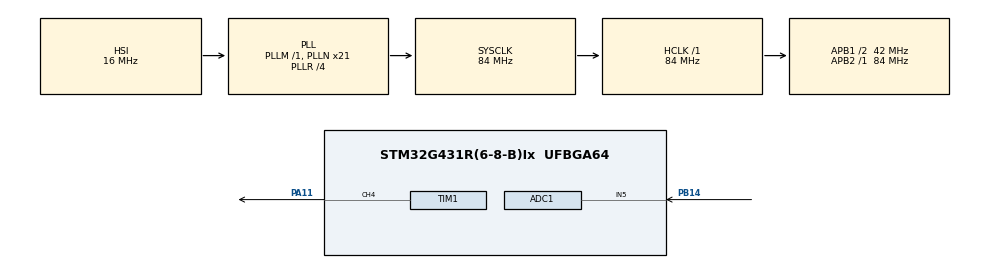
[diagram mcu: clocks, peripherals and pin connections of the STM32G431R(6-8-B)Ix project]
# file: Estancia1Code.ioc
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ADC1.Channel-1\#ChannelRegularConversion=ADC_CHANNEL_5
ADC1.NbrOfConversionFlag=1
ADC1.OffsetNumber-1\#ChannelRegularConversion=ADC_OFFSET_NONE
ADC1.Rank-1\#ChannelRegularConversion=1
ADC1.SamplingTime-1\#ChannelRegularConversion=ADC_SAMPLETIME_2CYCLES_5
ADC1.master=1
Mcu.Family=STM32G4
Mcu.Name=STM32G431R(6-8-B)Ix
Mcu.Package=UFBGA64
NVIC.PriorityGroup=NVIC_PRIORITYGROUP_4
PA11.Signal=S_TIM1_CH4
PA13.GPIO_Label=asd
PA13.Mode=Serial_Wire
PA13.Signal=SYS_JTMS-SWDIO
PA14.GPIO_Label=as
PA14.Mode=Serial_Wire
PA14.Signal=SYS_JTCK-SWCLK
PB14.Mode=IN5-Single-Ended
PB14.Signal=ADC1_IN5
ProjectManager.HeapSize=0x200
ProjectManager.StackSize=0x400
ProjectManager.TargetToolchain=STM32CubeIDE
RCC.ADC12Freq_Value=84000000
RCC.AHBFreq_Value=84000000
RCC.APB1CLKDivider=RCC_HCLK_DIV2
RCC.APB1Freq_Value=42000000
RCC.APB1TimFreq_Value=84000000
RCC.APB2Freq_Value=84000000
RCC.APB2TimFreq_Value=84000000
RCC.CortexFreq_Value=84000000
RCC.EXTERNAL_CLOCK_VALUE=12288000
RCC.HCLKFreq_Value=84000000
RCC.HSE_VALUE=8000000
RCC.HSI48_VALUE=48000000
RCC.HSI_VALUE=16000000
RCC.LSE_VALUE=32768
RCC.PLLN=21
RCC.PLLR=RCC_PLLR_DIV4
RCC.SYSCLKFreq_VALUE=84000000
RCC.SYSCLKSource=RCC_SYSCLKSOURCE_PLLCLK
RCC.USBFreq_Value=168000000
RCC.VCOOutputFreq_Value=336000000
SH.S_TIM1_CH4.0=TIM1_CH4,PWM Generation4 CH4
TIM1.Channel-PWM\ Generation4\ CH4=TIM_CHANNEL_4
VP_SYS_VS_DBSignals.Mode=DisableDeadBatterySignals
VP_TIM1_VS_ClockSourceINT.Mode=Internal
board=custom

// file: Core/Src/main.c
/* USER CODE BEGIN Header */
/**
  ******************************************************************************
  * @file           : main.c
  * @brief          : Main program body
  ******************************************************************************
  * @attention
  *
  * <h2><center>&copy; Copyright (c) 2021 STMicroelectronics.
  * All rights reserved.</center></h2>
  *
  * This software component is licensed by ST under BSD 3-Clause license,
  * the "License"; You may not use this file except in compliance with the
  * License. You may obtain a copy of the License at:
  *                        opensource.org/licenses/BSD-3-Clause
  *
  ******************************************************************************
  */
/* USER CODE END Header */
#include "main.h"

/* USER CODE BEGIN Includes */
#include "leds.h"
#include "motor.h"
#include "pwm.h"
#include "adc.h"
#include "lcd.h"
/* USER CODE END Includes */

ADC_HandleTypeDef hadc1;

TIM_HandleTypeDef htim1;

void SystemClock_Config(void);
static void MX_GPIO_Init(void);
static void MX_ADC1_Init(void);
static void MX_TIM1_Init(void);

int main(void)
{

  /* MCU Configuration--------------------------------------------------------*/

  /* Reset of all peripherals, Initializes the Flash interface and the Systick. */
  HAL_Init();

  /* Configure the system clock */
  SystemClock_Config();

  /* Initialize all configured peripherals */
  MX_GPIO_Init();
  MX_ADC1_Init();
  MX_TIM1_Init();
  /* USER CODE BEGIN 2 */

	vLcd_Init();
	vInit_Leds();
	vMotor_Init();
	vPwm_Init();

  /* USER CODE END 2 */

  /* Infinite loop */
  while (1)
  {

    /* USER CODE BEGIN 3 */
		vLedFunction();
		vDirection();
		vDecreaseAndCreaseVel();
		vConvertIntToASCII();
		HAL_Delay(1);
  }
  /* USER CODE END 3 */
}

void SystemClock_Config(void)
{
  RCC_OscInitTypeDef RCC_OscInitStruct = {0};
  RCC_ClkInitTypeDef RCC_ClkInitStruct = {0};
  RCC_PeriphCLKInitTypeDef PeriphClkInit = {0};

  /** Configure the main internal regulator output voltage
  */
  HAL_PWREx_ControlVoltageScaling(PWR_REGULATOR_VOLTAGE_SCALE1);
  /** Initializes the RCC Oscillators according to the specified parameters
  * in the RCC_OscInitTypeDef structure.
  */
  RCC_OscInitStruct.OscillatorType = RCC_OSCILLATORTYPE_HSI;
  RCC_OscInitStruct.HSIState = RCC_HSI_ON;
  RCC_OscInitStruct.HSICalibrationValue = RCC_HSICALIBRATION_DEFAULT;
  RCC_OscInitStruct.PLL.PLLState = RCC_PLL_ON;
  RCC_OscInitStruct.PLL.PLLSource = RCC_PLLSOURCE_HSI;
  RCC_OscInitStruct.PLL.PLLM = RCC_PLLM_DIV1;
  RCC_OscInitStruct.PLL.PLLN = 21;
  RCC_OscInitStruct.PLL.PLLP = RCC_PLLP_DIV2;
  RCC_OscInitStruct.PLL.PLLQ = RCC_PLLQ_DIV2;
  RCC_OscInitStruct.PLL.PLLR = RCC_PLLR_DIV4;
  if (HAL_RCC_OscConfig(&RCC_OscInitStruct) != HAL_OK)
  {
    Error_Handler();
  }
  /** Initializes the CPU, AHB and APB buses clocks
  */
  RCC_ClkInitStruct.ClockType = RCC_CLOCKTYPE_HCLK|RCC_CLOCKTYPE_SYSCLK
                              |RCC_CLOCKTYPE_PCLK1|RCC_CLOCKTYPE_PCLK2;
  RCC_ClkInitStruct.SYSCLKSource = RCC_SYSCLKSOURCE_PLLCLK;
  RCC_ClkInitStruct.AHBCLKDivider = RCC_SYSCLK_DIV1;
  RCC_ClkInitStruct.APB1CLKDivider = RCC_HCLK_DIV2;
  RCC_ClkInitStruct.APB2CLKDivider = RCC_HCLK_DIV1;

  if (HAL_RCC_ClockConfig(&RCC_ClkInitStruct, FLASH_LATENCY_2) != HAL_OK)
  {
    Error_Handler();
  }
  /** Initializes the peripherals clocks
  */
  PeriphClkInit.PeriphClockSelection = RCC_PERIPHCLK_ADC12;
  PeriphClkInit.Adc12ClockSelection = RCC_ADC12CLKSOURCE_SYSCLK;
  if (HAL_RCCEx_PeriphCLKConfig(&PeriphClkInit) != HAL_OK)
  {
    Error_Handler();
  }
}

static void MX_ADC1_Init(void)
{

  ADC_MultiModeTypeDef multimode = {0};
  ADC_ChannelConfTypeDef sConfig = {0};

  /** Common config
  */
  hadc1.Instance = ADC1;
  hadc1.Init.ClockPrescaler = ADC_CLOCK_SYNC_PCLK_DIV2;
  hadc1.Init.Resolution = ADC_RESOLUTION_12B;
  hadc1.Init.DataAlign = ADC_DATAALIGN_RIGHT;
  hadc1.Init.GainCompensation = 0;
  hadc1.Init.ScanConvMode = ADC_SCAN_DISABLE;
  hadc1.Init.EOCSelection = ADC_EOC_SINGLE_CONV;
  hadc1.Init.LowPowerAutoWait = DISABLE;
  hadc1.Init.ContinuousConvMode = DISABLE;
  hadc1.Init.NbrOfConversion = 1;
  hadc1.Init.DiscontinuousConvMode = DISABLE;
  hadc1.Init.ExternalTrigConv = ADC_SOFTWARE_START;
  hadc1.Init.ExternalTrigConvEdge = ADC_EXTERNALTRIGCONVEDGE_NONE;
  hadc1.Init.DMAContinuousRequests = DISABLE;
  hadc1.Init.Overrun = ADC_OVR_DATA_PRESERVED;
  hadc1.Init.OversamplingMode = DISABLE;
  if (HAL_ADC_Init(&hadc1) != HAL_OK)
  {
    Error_Handler();
  }
  /** Configure the ADC multi-mode
  */
  multimode.Mode = ADC_MODE_INDEPENDENT;
  if (HAL_ADCEx_MultiModeConfigChannel(&hadc1, &multimode) != HAL_OK)
  {
    Error_Handler();
  }
  /** Configure Regular Channel
  */
  sConfig.Channel = ADC_CHANNEL_5;
  sConfig.Rank = ADC_REGULAR_RANK_1;
  sConfig.SamplingTime = ADC_SAMPLETIME_2CYCLES_5;
  sConfig.SingleDiff = ADC_SINGLE_ENDED;
  sConfig.OffsetNumber = ADC_OFFSET_NONE;
  sConfig.Offset = 0;
  if (HAL_ADC_ConfigChannel(&hadc1, &sConfig) != HAL_OK)
  {
    Error_Handler();
  }

}

static void MX_TIM1_Init(void)
{

  TIM_ClockConfigTypeDef sClockSourceConfig = {0};
  TIM_MasterConfigTypeDef sMasterConfig = {0};
  TIM_OC_InitTypeDef sConfigOC = {0};
  TIM_BreakDeadTimeConfigTypeDef sBreakDeadTimeConfig = {0};

  htim1.Instance = TIM1;
  htim1.Init.Prescaler = 0;
  htim1.Init.CounterMode = TIM_COUNTERMODE_UP;
  htim1.Init.Period = 65535;
  htim1.Init.ClockDivision = TIM_CLOCKDIVISION_DIV1;
  htim1.Init.RepetitionCounter = 0;
  htim1.Init.AutoReloadPreload = TIM_AUTORELOAD_PRELOAD_DISABLE;
  if (HAL_TIM_Base_Init(&htim1) != HAL_OK)
  {
    Error_Handler();
  }
  sClockSourceConfig.ClockSource = TIM_CLOCKSOURCE_INTERNAL;
  if (HAL_TIM_ConfigClockSource(&htim1, &sClockSourceConfig) != HAL_OK)
  {
    Error_Handler();
  }
  if (HAL_TIM_PWM_Init(&htim1) != HAL_OK)
  {
    Error_Handler();
  }
  sMasterConfig.MasterOutputTrigger = TIM_TRGO_RESET;
  sMasterConfig.MasterOutputTrigger2 = TIM_TRGO2_RESET;
  sMasterConfig.MasterSlaveMode = TIM_MASTERSLAVEMODE_DISABLE;
  if (HAL_TIMEx_MasterConfigSynchronization(&htim1, &sMasterConfig) != HAL_OK)
  {
    Error_Handler();
  }
  sConfigOC.OCMode = TIM_OCMODE_PWM1;
  sConfigOC.Pulse = 0;
  sConfigOC.OCPolarity = TIM_OCPOLARITY_HIGH;
  sConfigOC.OCNPolarity = TIM_OCNPOLARITY_HIGH;
  sConfigOC.OCFastMode = TIM_OCFAST_DISABLE;
  sConfigOC.OCIdleState = TIM_OCIDLESTATE_RESET;
  sConfigOC.OCNIdleState = TIM_OCNIDLESTATE_RESET;
  if (HAL_TIM_PWM_ConfigChannel(&htim1, &sConfigOC, TIM_CHANNEL_4) != HAL_OK)
  {
    Error_Handler();
  }
  sBreakDeadTimeConfig.OffStateRunMode = TIM_OSSR_DISABLE;
  sBreakDeadTimeConfig.OffStateIDLEMode = TIM_OSSI_DISABLE;
  sBreakDeadTimeConfig.LockLevel = TIM_LOCKLEVEL_OFF;
  sBreakDeadTimeConfig.DeadTime = 0;
  sBreakDeadTimeConfig.BreakState = TIM_BREAK_DISABLE;
  sBreakDeadTimeConfig.BreakPolarity = TIM_BREAKPOLARITY_HIGH;
  sBreakDeadTimeConfig.BreakFilter = 0;
  sBreakDeadTimeConfig.BreakAFMode = TIM_BREAK_AFMODE_INPUT;
  sBreakDeadTimeConfig.Break2State = TIM_BREAK2_DISABLE;
  sBreakDeadTimeConfig.Break2Polarity = TIM_BREAK2POLARITY_HIGH;
  sBreakDeadTimeConfig.Break2Filter = 0;
  sBreakDeadTimeConfig.Break2AFMode = TIM_BREAK_AFMODE_INPUT;
  sBreakDeadTimeConfig.AutomaticOutput = TIM_AUTOMATICOUTPUT_DISABLE;
  if (HAL_TIMEx_ConfigBreakDeadTime(&htim1, &sBreakDeadTimeConfig) != HAL_OK)
  {
    Error_Handler();
  }
  HAL_TIM_MspPostInit(&htim1);

}

static void MX_GPIO_Init(void)
{

  /* GPIO Ports Clock Enable */
  __HAL_RCC_GPIOA_CLK_ENABLE();
  __HAL_RCC_GPIOB_CLK_ENABLE();

}

void Error_Handler(void)
{
}

/************************ (C) COPYRIGHT STMicroelectronics *****END OF FILE****/
